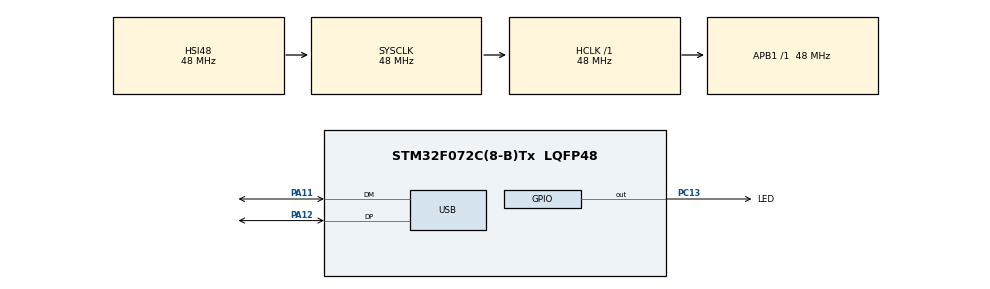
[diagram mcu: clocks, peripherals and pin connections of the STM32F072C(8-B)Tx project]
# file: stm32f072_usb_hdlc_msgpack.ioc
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Mcu.Family=STM32F0
Mcu.Name=STM32F072C(8-B)Tx
Mcu.Package=LQFP48
NVIC.USB_IRQn=true\:0\:0\:false\:false\:true\:false\:true
PA11.Mode=Device
PA11.Signal=USB_DM
PA12.Mode=Device
PA12.Signal=USB_DP
PA13.Mode=Serial_Wire
PA13.Signal=SYS_SWDIO
PA14.Mode=Serial_Wire
PA14.Signal=SYS_SWCLK
PC13.GPIO_Label=LED
PC13.Signal=GPIO_Output
ProjectManager.HeapSize=0x200
ProjectManager.StackSize=0x400
ProjectManager.TargetToolchain=TrueSTUDIO
RCC.AHBFreq_Value=48000000
RCC.APB1Freq_Value=48000000
RCC.APB1TimFreq_Value=48000000
RCC.HCLKFreq_Value=48000000
RCC.SYSCLKFreq_VALUE=48000000
RCC.SYSCLKSource=RCC_SYSCLKSOURCE_HSI48
USB_DEVICE.CLASS_NAME_FS=CDC
USB_DEVICE.MANUFACTURER_STRING=NEWTON FOUNDATION
USB_DEVICE.PRODUCT_STRING_CDC_FS=MsgPack
USB_DEVICE.SERIALNUMBER_STRING_CDC_FS=16888999
USB_DEVICE.VirtualMode=Cdc
USB_DEVICE.VirtualModeFS=Cdc_FS
VP_USB_DEVICE_VS_USB_DEVICE_CDC_FS.Mode=CDC_FS
board=custom

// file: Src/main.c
/* USER CODE BEGIN Header */
/**
 ******************************************************************************
 * @file           : main.c
 * @brief          : Main program body
 ******************************************************************************
 * This notice applies to any and all portions of this file
 * that are not between comment pairs USER CODE BEGIN and
 * USER CODE END. Other portions of this file, whether
 * inserted by the user or by software development tools
 * are owned by their respective copyright owners.
 *
 * Copyright (c) 2019 STMicroelectronics International N.V.
 * All rights reserved.
 *
 * Redistribution and use in source and binary forms, with or without
 * modification, are permitted, provided that the following conditions are met:
 *
 * 1. Redistribution of source code must retain the above copyright notice,
 *    this list of conditions and the following disclaimer.
 * 2. Redistributions in binary form must reproduce the above copyright notice,
 *    this list of conditions and the following disclaimer in the documentation
 *    and/or other materials provided with the distribution.
 * 3. Neither the name of STMicroelectronics nor the names of other
 *    contributors to this software may be used to endorse or promote products
 *    derived from this software without specific written permission.
 * 4. This software, including modifications and/or derivative works of this
 *    software, must execute solely and exclusively on microcontroller or
 *    microprocessor devices manufactured by or for STMicroelectronics.
 * 5. Redistribution and use of this software other than as permitted under
 *    this license is void and will automatically terminate your rights under
 *    this license.
 *
 * THIS SOFTWARE IS PROVIDED BY STMICROELECTRONICS AND CONTRIBUTORS "AS IS"
 * AND ANY EXPRESS, IMPLIED OR STATUTORY WARRANTIES, INCLUDING, BUT NOT
 * LIMITED TO, THE IMPLIED WARRANTIES OF MERCHANTABILITY, FITNESS FOR A
 * PARTICULAR PURPOSE AND NON-INFRINGEMENT OF THIRD PARTY INTELLECTUAL PROPERTY
 * RIGHTS ARE DISCLAIMED TO THE FULLEST EXTENT PERMITTED BY LAW. IN NO EVENT
 * SHALL STMICROELECTRONICS OR CONTRIBUTORS BE LIABLE FOR ANY DIRECT, INDIRECT,
 * INCIDENTAL, SPECIAL, EXEMPLARY, OR CONSEQUENTIAL DAMAGES (INCLUDING, BUT NOT
 * LIMITED TO, PROCUREMENT OF SUBSTITUTE GOODS OR SERVICES; LOSS OF USE, DATA,
 * OR PROFITS; OR BUSINESS INTERRUPTION) HOWEVER CAUSED AND ON ANY THEORY OF
 * LIABILITY, WHETHER IN CONTRACT, STRICT LIABILITY, OR TORT (INCLUDING
 * NEGLIGENCE OR OTHERWISE) ARISING IN ANY WAY OUT OF THE USE OF THIS SOFTWARE,
 * EVEN IF ADVISED OF THE POSSIBILITY OF SUCH DAMAGE.
 *
 ******************************************************************************
 */
/* USER CODE END Header */

#include "main.h"
#include "usb_device.h"
#include "gpio.h"

/* USER CODE BEGIN Includes */
#include "misc_utils.h"
#include "circular-byte-buffer.h"
#include "minihdlc.h"
#include "usbd_cdc_if.h"
#include "cmp.h"
#include "cmp_utils.h"
/* USER CODE END Includes */

/* USER CODE BEGIN PV */
gpio_t led = { LED_GPIO_Port, LED_Pin };
/* USER CODE END PV */

void SystemClock_Config(void);

/* USER CODE BEGIN 0 */

#define MAX_CDC_BUFFER_SIZE 255

CIRC_BBUF_DEF(cdc_buffer, MAX_CDC_BUFFER_SIZE);

cmp_ctx_t cmp_ctx;
cmp_buffer_t cmp_buffer;

void cmp_send_response(cmp_ctx_t *cmp) {
	cmp_buffer_t *buffer = cmp->buf;
	minihdlc_send_frame_to_buffer(buffer->data, buffer->position);
	CDC_Transmit_FS(minihdlc_get_buffer(), minihdlc_get_buffer_size());
	cmp_buffer_init(&cmp_buffer);
}

void process_request(const uint8_t *frame_data, uint16_t frame_length) {
	cmp_buffer_fill(&cmp_buffer, frame_data, frame_length);
	cmp_buffer_rewind(&cmp_buffer);
	hex_dump(frame_data, frame_length);
	if (cmp_process_request(&cmp_ctx) == true) {
		cmp_send_response(&cmp_ctx);
	} else {
		;
	}
}

void cdc_buffer_push(uint8_t *data, uint32_t length) {
	for (int i = 0; i < length; i++) {
		if (circ_bbuf_push(&cdc_buffer, data[i]) != 0) {
			printf("Warning: circ_bbuf is full!\n");
		}
	}
}

/* USER CODE END 0 */

int main(void) {

	/* MCU Configuration--------------------------------------------------------*/

	/* Reset of all peripherals, Initializes the Flash interface and the Systick. */
	HAL_Init();

	/* Configure the system clock */
	SystemClock_Config();

	/* Initialize all configured peripherals */
	MX_GPIO_Init();
	MX_USB_DEVICE_Init();
	/* USER CODE BEGIN 2 */

	minihdlc_init(NULL, process_request);
	cmp_simple_init(&cmp_ctx, &cmp_buffer);

	/* USER CODE END 2 */

	/* Infinite loop */
	while (1) {

		/* USER CODE BEGIN 3 */
		uint8_t data;
		while (circ_bbuf_pop(&cdc_buffer, &data) == 0) {
			minihdlc_char_receiver(data);
		}
	}
	/* USER CODE END 3 */
}

void SystemClock_Config(void) {
	RCC_OscInitTypeDef RCC_OscInitStruct = { 0 };
	RCC_ClkInitTypeDef RCC_ClkInitStruct = { 0 };
	RCC_PeriphCLKInitTypeDef PeriphClkInit = { 0 };

	/** Initializes the CPU, AHB and APB busses clocks
	 */
	RCC_OscInitStruct.OscillatorType = RCC_OSCILLATORTYPE_HSI48;
	RCC_OscInitStruct.HSI48State = RCC_HSI48_ON;
	RCC_OscInitStruct.PLL.PLLState = RCC_PLL_NONE;
	if (HAL_RCC_OscConfig(&RCC_OscInitStruct) != HAL_OK) {
		Error_Handler();
	}
	/** Initializes the CPU, AHB and APB busses clocks
	 */
	RCC_ClkInitStruct.ClockType = RCC_CLOCKTYPE_HCLK | RCC_CLOCKTYPE_SYSCLK
			| RCC_CLOCKTYPE_PCLK1;
	RCC_ClkInitStruct.SYSCLKSource = RCC_SYSCLKSOURCE_HSI48;
	RCC_ClkInitStruct.AHBCLKDivider = RCC_SYSCLK_DIV1;
	RCC_ClkInitStruct.APB1CLKDivider = RCC_HCLK_DIV1;

	if (HAL_RCC_ClockConfig(&RCC_ClkInitStruct, FLASH_LATENCY_1) != HAL_OK) {
		Error_Handler();
	}
	PeriphClkInit.PeriphClockSelection = RCC_PERIPHCLK_USB;
	PeriphClkInit.UsbClockSelection = RCC_USBCLKSOURCE_HSI48;

	if (HAL_RCCEx_PeriphCLKConfig(&PeriphClkInit) != HAL_OK) {
		Error_Handler();
	}
}

void Error_Handler(void) {
}

/************************ (C) COPYRIGHT STMicroelectronics *****END OF FILE****/
